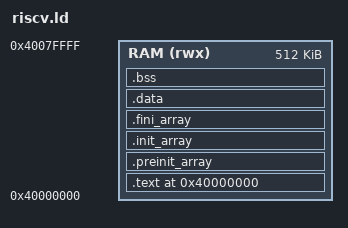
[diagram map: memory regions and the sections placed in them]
ENTRY(_entry)

MEMORY {
    RAM(rwx) : ORIGIN = 0x40000000, LENGTH = 512K
}

__stacktop = ORIGIN(RAM) + LENGTH(RAM);
__data_load = LOADADDR(.data);


SECTIONS {
    . = ORIGIN(RAM);
    .text : {
        KEEP(*(.vectors))
        KEEP(*(.vectors*))
        KEEP(*(.text))
        . = ALIGN(4);
        *(.text*)
        . = ALIGN(4);
        KEEP(*(.rodata))
        *(.rodata*)
        . = ALIGN(4);
    } > RAM

    .preinit_array ALIGN(4): {
        __preinit_array_start = .;
        KEEP(*(.preinit_array))
        __preinit_array_end = .;
    } > RAM

    .init_array ALIGN(4): {
        __init_array_start = .;
        KEEP(*(.init_array))
        __init_array_end = .;
    } > RAM

    .fini_array ALIGN(4): {
        __fini_array_start = .;
        KEEP(*(.fini_array))
        __fini_array_end = .;
    } > RAM

    .data ALIGN(4) : {
        __data_start = .;
        *(.data)
        *(.data*)
        . = ALIGN(4);
        __data_end = .;
    } > RAM

    .bss ALIGN(4) (NOLOAD) : {
        __bss_start = .;
        *(.bss)
        *(.bss*)
        . = ALIGN(4);
        __bss_end = .;
        *(.noinit)
        *(.noinit*)
    } > RAM

    . = ALIGN(4);
    __heap_start = .;

}
